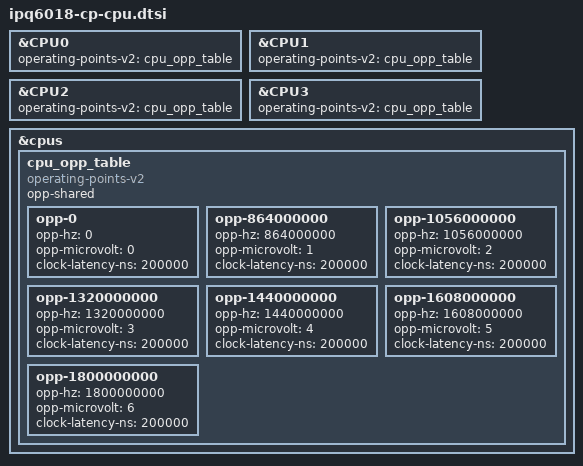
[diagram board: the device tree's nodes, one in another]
/*
 * Copyright (c) 2019, The Linux Foundation. All rights reserved.
 *
 * Permission to use, copy, modify, and/or distribute this software for any
 * purpose with or without fee is hereby granted, provided that the above
 * copyright notice and this permission notice appear in all copies.
 *
 * THE SOFTWARE IS PROVIDED "AS IS" AND THE AUTHOR DISCLAIMS ALL WARRANTIES
 * WITH REGARD TO THIS SOFTWARE INCLUDING ALL IMPLIED WARRANTIES OF
 * MERCHANTABILITY AND FITNESS. IN NO EVENT SHALL THE AUTHOR BE LIABLE FOR
 * ANY SPECIAL, DIRECT, INDIRECT, OR CONSEQUENTIAL DAMAGES OR ANY DAMAGES
 * WHATSOEVER RESULTING FROM LOSS OF USE, DATA OR PROFITS, WHETHER IN AN
 * ACTION OF CONTRACT, NEGLIGENCE OR OTHER TORTIOUS ACTION, ARISING OUT OF
 * OR IN CONNECTION WITH THE USE OR PERFORMANCE OF THIS SOFTWARE.
 */

&CPU0 {
	operating-points-v2 = <&cpu_opp_table>;
};

&CPU1 {
	operating-points-v2 = <&cpu_opp_table>;
};

&CPU2 {
	operating-points-v2 = <&cpu_opp_table>;
};

&CPU3 {
	operating-points-v2 = <&cpu_opp_table>;
};

&cpus {
	cpu_opp_table: cpu_opp_table {
		compatible = "operating-points-v2";
		opp-shared;

		opp-0 {
			opp-hz = /bits/ 64 <0>;
			opp-microvolt = <0>;
			clock-latency-ns = <200000>;
		};
		opp-864000000 {
			opp-hz = /bits/ 64 <864000000>;
			opp-microvolt = <1>;
			clock-latency-ns = <200000>;
		};
		opp-1056000000 {
			opp-hz = /bits/ 64 <1056000000>;
			opp-microvolt = <2>;
			clock-latency-ns = <200000>;
		};
		opp-1320000000 {
			opp-hz = /bits/ 64 <1320000000>;
			opp-microvolt = <3>;
			clock-latency-ns = <200000>;
		};
		opp-1440000000 {
			opp-hz = /bits/ 64 <1440000000>;
			opp-microvolt = <4>;
			clock-latency-ns = <200000>;
		};
		opp-1608000000 {
			opp-hz = /bits/ 64 <1608000000>;
			opp-microvolt = <5>;
			clock-latency-ns = <200000>;
		};
		opp-1800000000 {
			opp-hz = /bits/ 64 <1800000000>;
			opp-microvolt = <6>;
			clock-latency-ns = <200000>;
		};
	};
};
